# MIMXRT1062 register map
Vendor: nxp.com; File version: 1.0
CPU: CM7 r0p1, little endian, MPU, FPU, VTOR, 4 interrupt priority bits
Registers are 32-bit, read-write, reset 0x0 unless marked. A register's access mark holds for its fields unless they carry their own. Offsets are from the block's base; [hi:lo] are bit positions.

## ENC1 — Quadrature Decoder
Base 0x403C8000; register names take the prefix ENC1_
Same registers: ENC2 0x403CC000 (register names take the prefix ENC2_), ENC3 0x403D0000 (register names take the prefix ENC3_), ENC4 0x403D4000 (register names take the prefix ENC4_)
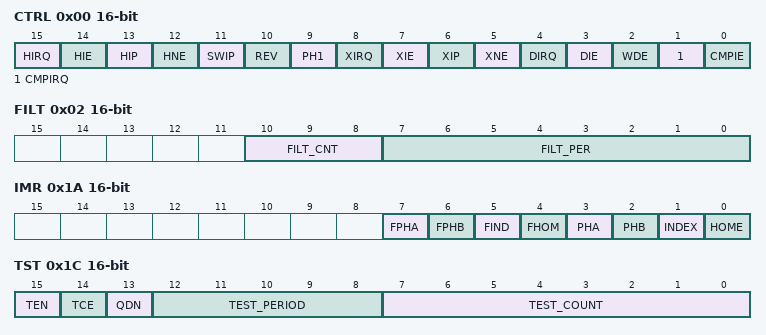
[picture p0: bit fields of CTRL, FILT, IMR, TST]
0x00 CTRL 16-bit — Control Register
  [15] HIRQ write-1-clears — HOME Signal Transition Interrupt Request
    0=No interrupt; 1=HOME signal transition interrupt request
  [14] HIE — HOME Interrupt Enable
    0=Disable HOME interrupts; 1=Enable HOME interrupts
  [13] HIP — Enable HOME to Initialize Position Counters UPOS and LPOS
    0=No action; 1=HOME signal initializes the position counter
  [12] HNE — Use Negative Edge of HOME Input
    0=Use positive going edge-to-trigger initialization of position counters UPOS and LPOS; 1=Use negative going edge-to-trigger initialization of position counters UPOS and LPOS
  [11] SWIP — Software Triggered Initialization of Position Counters UPOS and LPOS
    0=No action; 1=Initialize position counter
  [10] REV — Enable Reverse Direction Counting
    0=Count normally; 1=Count in the reverse direction
  [9] PH1 — Enable Signal Phase Count Mode
    0=Use standard quadrature decoder where PHASEA and PHASEB represent a two phase quadrature signal; 1=Bypass the quadrature decoder. A positive transition of the PHASEA input generates a count signal. The PHASEB input and the REV bit control the counter direction. If CTRL[REV] = 0, PHASEB = 0, then count up If CTRL[REV] = 0, PHASEB = 1, then count down If CTRL[REV] = 1, PHASEB = 0, then count down If CTRL[REV] = 1, PHASEB = 1, then count up
  [8] XIRQ write-1-clears — INDEX Pulse Interrupt Request
    0=No interrupt has occurred; 1=INDEX pulse interrupt has occurred
  [7] XIE — INDEX Pulse Interrupt Enable
    0=INDEX pulse interrupt is disabled; 1=INDEX pulse interrupt is enabled
  [6] XIP — INDEX Triggered Initialization of Position Counters UPOS and LPOS
    0=No action; 1=INDEX pulse initializes the position counter
  [5] XNE — Use Negative Edge of INDEX Pulse
    0=Use positive transition edge of INDEX pulse; 1=Use negative transition edge of INDEX pulse
  [4] DIRQ write-1-clears — Watchdog Timeout Interrupt Request
    0=No interrupt has occurred; 1=Watchdog timeout interrupt has occurred
  [3] DIE — Watchdog Timeout Interrupt Enable
    0=Watchdog timer interrupt is disabled; 1=Watchdog timer interrupt is enabled
  [2] WDE — Watchdog Enable
    0=Watchdog timer is disabled; 1=Watchdog timer is enabled
  [1] CMPIRQ write-1-clears — Compare Interrupt Request
    0=No match has occurred; 1=COMP match has occurred
  [0] CMPIE — Compare Interrupt Enable
    0=Compare interrupt is disabled; 1=Compare interrupt is enabled
0x02 FILT 16-bit — Input Filter Register
  [10:8] FILT_CNT — Input Filter Sample Count
  [7:0] FILT_PER — Input Filter Sample Period
0x04 WTR 16-bit — Watchdog Timeout Register
  [15:0] WDOG — WDOG[15:0] is a binary representation of the number of clock cycles plus one that the watchdog timer counts before timing out and optionally generating an interrupt
0x06 POSD 16-bit — Position Difference Counter Register
  [15:0] POSD — This read/write register contains the position change in value occurring between each read of the position register
0x08 POSDH 16-bit ro — Position Difference Hold Register
  [15:0] POSDH — This read-only register contains a snapshot of the value of the POSD register
0x0A REV 16-bit — Revolution Counter Register
  [15:0] REV — This read/write register contains the current value of the revolution counter.
0x0C REVH 16-bit ro — Revolution Hold Register
  [15:0] REVH — This read-only register contains a snapshot of the value of the REV register.
0x0E UPOS 16-bit — Upper Position Counter Register
  [15:0] POS — This read/write register contains the upper (most significant) half of the position counter
0x10 LPOS 16-bit — Lower Position Counter Register
  [15:0] POS — This read/write register contains the lower (least significant) half of the position counter
0x12 UPOSH 16-bit ro — Upper Position Hold Register
  [15:0] POSH — This read-only register contains a snapshot of the UPOS register.
0x14 LPOSH 16-bit ro — Lower Position Hold Register
  [15:0] POSH — This read-only register contains a snapshot of the LPOS register.
0x16 UINIT 16-bit — Upper Initialization Register
  [15:0] INIT — This read/write register contains the value to be used to initialize the upper half of the position counter (UPOS)
0x18 LINIT 16-bit — Lower Initialization Register
  [15:0] INIT — This read/write register contains the value to be used to initialize the lower half of the position counter (LPOS)
0x1A IMR 16-bit ro — Input Monitor Register
  [7] FPHA — This is the filtered version of PHASEA input.
  [6] FPHB — This is the filtered version of PHASEB input.
  [5] FIND — This is the filtered version of INDEX input.
  [4] FHOM — This is the filtered version of HOME input.
  [3] PHA — This is the raw PHASEA input.
  [2] PHB — This is the raw PHASEB input.
  [1] INDEX — This is the raw INDEX input.
  [0] HOME — This is the raw HOME input.
0x1C TST 16-bit — Test Register
  [15] TEN — Test Mode Enable
    0=Test module is not enabled; 1=Test module is enabled
  [14] TCE — Test Counter Enable
    0=Test count is not enabled; 1=Test count is enabled
  [13] QDN — Quadrature Decoder Negative Signal
    0=Leaves quadrature decoder signal in a positive direction; 1=Generates a negative quadrature decoder signal
  [12:8] TEST_PERIOD — These bits hold the period of quadrature phase in IPBus clock cycles.
  [7:0] TEST_COUNT — These bits hold the number of quadrature advances to generate.
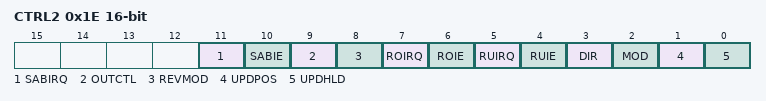
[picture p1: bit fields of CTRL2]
0x1E CTRL2 16-bit — Control 2 Register
  [11] SABIRQ write-1-clears — Simultaneous PHASEA and PHASEB Change Interrupt Request
    0=No simultaneous change of PHASEA and PHASEB has occurred; 1=A simultaneous change of PHASEA and PHASEB has occurred
  [10] SABIE — Simultaneous PHASEA and PHASEB Change Interrupt Enable
    0=Simultaneous PHASEA and PHASEB change interrupt disabled; 1=Simultaneous PHASEA and PHASEB change interrupt enabled
  [9] OUTCTL — Output Control
    0=POSMATCH pulses when a match occurs between the position counters (POS) and the compare value (COMP); 1=POSMATCH pulses when the UPOS, LPOS, REV, or POSD registers are read
  [8] REVMOD — Revolution Counter Modulus Enable
    0=Use INDEX pulse to increment/decrement revolution counter (REV); 1=Use modulus counting roll-over/under to increment/decrement revolution counter (REV)
  [7] ROIRQ write-1-clears — Roll-over Interrupt Request
    0=No roll-over has occurred; 1=Roll-over has occurred
  [6] ROIE — Roll-over Interrupt Enable
    0=Roll-over interrupt is disabled; 1=Roll-over interrupt is enabled
  [5] RUIRQ write-1-clears — Roll-under Interrupt Request
    0=No roll-under has occurred; 1=Roll-under has occurred
  [4] RUIE — Roll-under Interrupt Enable
    0=Roll-under interrupt is disabled; 1=Roll-under interrupt is enabled
  [3] DIR ro — Count Direction Flag
    0=Last count was in the down direction; 1=Last count was in the up direction
  [2] MOD — Enable Modulo Counting
    0=Disable modulo counting; 1=Enable modulo counting
  [1] UPDPOS — Update Position Registers
    0=No action for POSD, REV, UPOS and LPOS on rising edge of TRIGGER; 1=Clear POSD, REV, UPOS and LPOS on rising edge of TRIGGER
  [0] UPDHLD — Update Hold Registers
    0=Disable updates of hold registers on rising edge of TRIGGER; 1=Enable updates of hold registers on rising edge of TRIGGER
0x20 UMOD 16-bit — Upper Modulus Register
  [15:0] MOD — This read/write register contains the upper (most significant) half of the modulus register
0x22 LMOD 16-bit — Lower Modulus Register
  [15:0] MOD — This read/write register contains the lower (least significant) half of the modulus register
0x24 UCOMP 16-bit reset 0xFFFF — Upper Position Compare Register
  [15:0] COMP — This read/write register contains the upper (most significant) half of the position compare register
0x26 LCOMP 16-bit reset 0xFFFF — Lower Position Compare Register
  [15:0] COMP — This read/write register contains the lower (least significant) half of the position compare register
